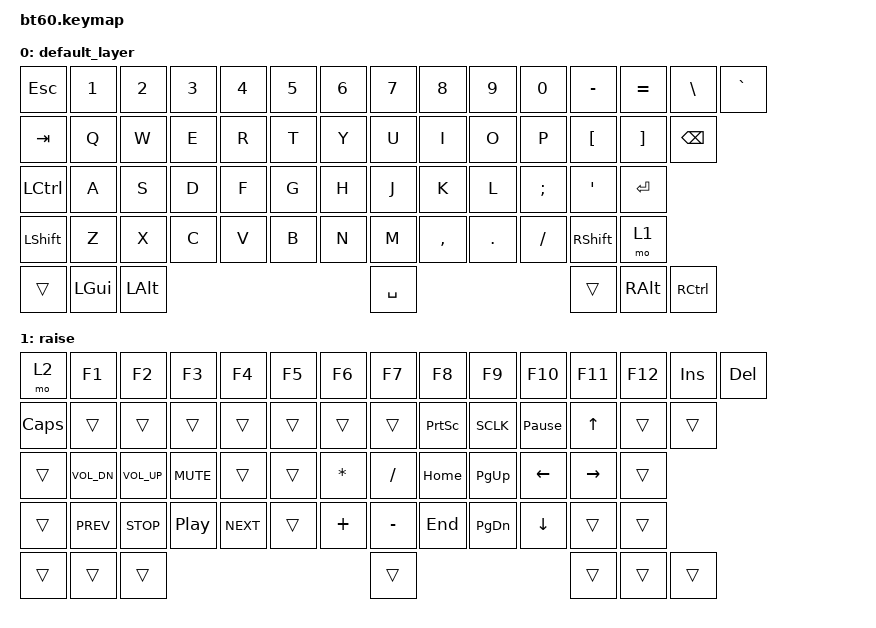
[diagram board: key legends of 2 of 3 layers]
#include <behaviors.dtsi>
#include <dt-bindings/zmk/keys.h>
#include <dt-bindings/zmk/bt.h>
#include <dt-bindings/zmk/outputs.h>

/ {
    behaviors {
        lst: layer_sticky_tap {
            compatible = "zmk,behavior-hold-tap";
            label = "LAYER_STICKY_TAP";
            #binding-cells = <2>;
            tapping-term-ms = <175>;
            quick_tap_ms = <0>;
            flavor = "hold-preferred";
            bindings = <&mo>, <&sk>;
        };

    };

    // combos {
    //     compatible = "zmk,combos";
    //     combo_bootloader {
    //         timeout-ms = <50>;
    //         key-positions = <54 0 28>;
    //         bindings = <&bootloader>;
    //     };
    // };

    keymap {
        compatible = "zmk,keymap";

        default_layer {
                // ------------------------------------------------------------------------------------------
                // | ESC |  1  |  2  |  3  |  4  |  5  |  6  |  7  |  8  |  9  |  0  |  -  |  =  |  \  | `  |
                // | TAB  |  Q  |  W  |  E  |  R  |  T  |  Y  |  U  |  I  |  O  |  P  |  [  |  ]  |  BSPC   |
                // | CTRL  |  A  |  S  |  D  |  F  |  G  |  H  |  J  |  K  |  L  |  ;  |  '  |      ENTER   |
                // |  SHIFT    |  Z  |  X  |  C  |  V  |  B  |  N  |  M  |  ,  |  .  | /   | SHIFT |   1    |
                // |        |  WIN  |  ALT |                     SPACE               |   ALT  | CTRL |      |
                // ------------------------------------------------------------------------------------------
            bindings = <
                &kp ESC       &kp N1          &kp N2          &kp N3        &kp N4    &kp N5    &kp N6    &kp N7    &kp  N8      &kp  N9     &kp  N0       &kp MINUS     &kp EQUAL          &kp BSLH    &kp GRAVE
                &kp TAB       &kp Q           &kp W           &kp E         &kp R     &kp T     &kp Y     &kp U     &kp  I       &kp  O      &kp  P        &kp LBKT      &kp RBKT           &kp BSPC
                &kp LCTRL     &kp A           &kp S           &kp D         &kp F     &kp G     &kp H     &kp J     &kp  K       &kp  L      &kp SEMI      &kp SQT       &kp RET
                &kp LSHFT     &kp Z           &kp X           &kp C         &kp V     &kp B     &kp N     &kp M     &kp COMMA    &kp DOT     &kp FSLH      &kp RSHFT     &mo 1
                &trans        &kp LGUI     &kp LALT                                                       &kp SPACE                                        &trans        &kp RALT           &kp RCTL
            >;
            sensor-bindings = <&inc_dec_kp C_VOL_UP C_VOL_DN>;
        };
        raise {
            bindings = <
                &mo 2         &kp F1          &kp F2          &kp F3        &kp F4    &kp F5    &kp F6    &kp F7    &kp F8       &kp F9      &kp F10       &kp F11       &kp F12            &kp INS      &kp DEL
                &kp CLCK      &trans          &trans          &trans        &trans    &trans    &trans    &trans    &kp PSCRN    &kp SCLK  &kp PAUSE_BREAK &kp UP        &trans             &trans
                &trans        &kp C_VOL_DN    &kp C_VOL_UP    &kp C_MUTE    &trans    &trans    &kp STAR  &kp SLASH &kp HOME     &kp PG_UP   &kp LEFT      &kp RIGHT     &trans
                &trans        &kp C_PREV      &kp C_STOP      &kp C_PP     &kp C_NEXT &trans    &kp PLUS  &kp MINUS &kp END      &kp PG_DN   &kp DOWN      &trans        &trans
                &trans        &trans          &trans                                                      &trans                                           &trans        &trans             &trans
            >;
            sensor-bindings = <&inc_dec_kp C_VOL_UP C_VOL_DN>;
        };
        
        // fnmod {
        // 	bindings = <
        // 		&trans        &kp F1          &kp F2          &kp F3        &kp F4    &kp F5    &kp F6    &kp F7    &kp F8       &kp F9      &kp F10       &kp F11       &kp F12            &trans       &trans
        // 		&trans        &trans          &trans          &trans        &trans    &trans    &trans    &trans    &trans       &trans      &trans        &trans        &trans             &trans
        // 		&trans        &trans          &trans          &trans        &trans    &trans    &trans    &trans    &trans       &trans      &trans        &trans
        // 		&trans        &trans          &trans          &trans        &trans    &trans    &trans    &trans    &trans       &trans      &trans        &trans        &trans
        // 		&trans        &trans          &trans                                                      &trans                                           &trans        &trans             &trans
        // 	>;
        // 	sensor-bindings = <&inc_dec_kp C_VOL_UP C_VOL_DN>;
        // };
        
        // amod {
        //	bindings = <
        //		&trans        &trans          &trans          &trans        &trans    &trans    &trans    &trans    &trans       &trans      &trans        &trans        &trans             &trans       &trans
        //		&trans        &trans          &trans          &trans        &trans    &trans    &trans    &trans    &trans       &trans      &trans        &kp UP        &trans             &trans
        //		&trans        &trans          &trans          &trans        &trans    &trans    &trans    &trans    &trans       &trans      &kp LEFT      &kp RIGHT
        //		&trans        &trans          &trans          &trans        &trans    &trans    &trans    &trans    &trans       &trans      &kp DOWN      &trans        &trans
        //		&trans        &trans          &trans                                                      &trans                                           &trans        &trans             &trans
        //	>;
        //	sensor-bindings = <&inc_dec_kp C_VOL_UP C_VOL_DN>;
        // };
        
        bt {
            bindings = <
                &trans      &bt BT_SEL 0  &bt BT_SEL 1  &bt BT_SEL 2  &bt BT_SEL 3 &bt BT_SEL 4 &trans    &trans    &trans       &trans      &trans        &trans        &trans              &trans       &bt BT_CLR
                &trans        &trans          &trans          &trans        &trans    &trans    &trans    &trans    &trans       &trans      &trans        &out OUT_USB  &out OUT_BLE        &reset
                &trans        &trans          &trans          &trans        &trans    &trans    &trans    &trans    &trans       &trans      &trans        &bootloader 
                &trans        &trans          &trans          &trans        &trans    &trans    &trans    &trans    &trans       &trans      &trans        &trans        &trans
                &trans        &trans          &trans                                                      &trans                                           &trans        &trans              &trans
            >;
            sensor-bindings = <&inc_dec_kp C_VOL_UP C_VOL_DN>;
        };
    };
};
